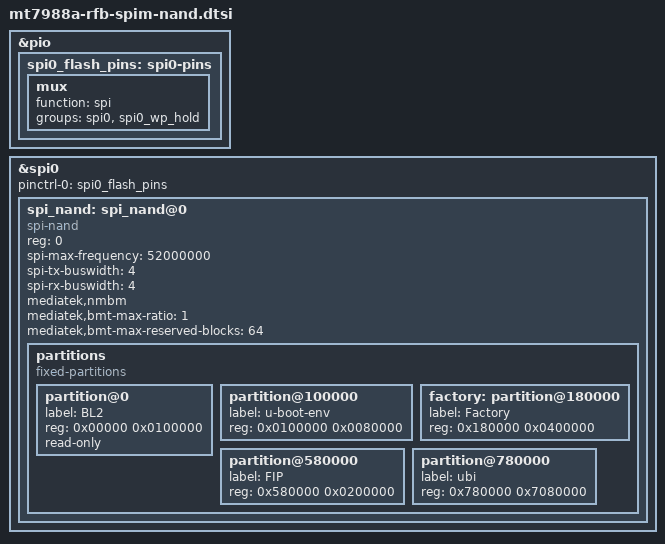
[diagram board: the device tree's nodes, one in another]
// SPDX-License-Identifier: (GPL-2.0 OR MIT)
/*
 * Copyright (C) 2022 MediaTek Inc.
 * Author: Sam.Shih <sam.shih@mediatek.com>
 */

/dts-v1/;
#include "mt7988a-rfb.dtsi"

&pio {
	spi0_flash_pins: spi0-pins {
		mux {
			function = "spi";
			groups = "spi0", "spi0_wp_hold";
		};
	};
};

&spi0 {
	pinctrl-names = "default";
	pinctrl-0 = <&spi0_flash_pins>;
	status = "okay";

	spi_nand: spi_nand@0 {
		compatible = "spi-nand";
		reg = <0>;
		spi-max-frequency = <52000000>;
		spi-tx-buswidth = <4>;
		spi-rx-buswidth = <4>;
	};

};

&spi_nand {
	mediatek,nmbm;
	mediatek,bmt-max-ratio = <1>;
	mediatek,bmt-max-reserved-blocks = <64>;

	partitions {
		compatible = "fixed-partitions";
		#address-cells = <1>;
		#size-cells = <1>;

		partition@0 {
			label = "BL2";
			reg = <0x00000 0x0100000>;
			read-only;
		};

		partition@100000 {
			label = "u-boot-env";
			reg = <0x0100000 0x0080000>;
		};

		factory: partition@180000 {
			label = "Factory";
			reg = <0x180000 0x0400000>;
		};

		partition@580000 {
			label = "FIP";
			reg = <0x580000 0x0200000>;
		};

		partition@780000 {
			label = "ubi";
			reg = <0x780000 0x7080000>;
		};
	};
};
